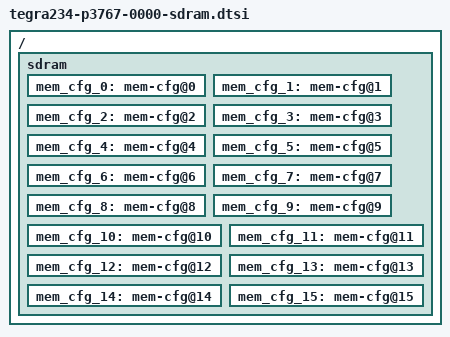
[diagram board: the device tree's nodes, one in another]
/*
 * SPDX-FileCopyrightText: Copyright (c) 2022 NVIDIA CORPORATION & AFFILIATES. All rights reserved.
 * SPDX-License-Identifier: LicenseRef-NvidiaProprietary
 *
 * NVIDIA CORPORATION, its affiliates and licensors retain all intellectual
 * property and proprietary rights in and to this material, related
 * documentation and any modifications thereto. Any use, reproduction,
 * disclosure or distribution of this material and related documentation
 * without an express license agreement from NVIDIA CORPORATION or
 * its affiliates is strictly prohibited.
 */

/ {
	sdram {
		mem_cfg_0: mem-cfg@0 {
		#include "tegra234-mb1-bct-p3767-0000-rc00-665mhz.dtsi"
		};

		mem_cfg_1: mem-cfg@1 {
		};

		mem_cfg_2: mem-cfg@2 {
		};

		mem_cfg_3: mem-cfg@3 {
		};

		mem_cfg_4: mem-cfg@4 {
		};

		mem_cfg_5: mem-cfg@5 {
		};

		mem_cfg_6: mem-cfg@6 {
		};

		mem_cfg_7: mem-cfg@7 {
		};

		mem_cfg_8: mem-cfg@8 {
		};

		mem_cfg_9: mem-cfg@9 {
		};

		mem_cfg_10: mem-cfg@10 {
		};

		mem_cfg_11: mem-cfg@11 {
		};

		mem_cfg_12: mem-cfg@12 {
		};

		mem_cfg_13: mem-cfg@13 {
		};

		mem_cfg_14: mem-cfg@14 {
		};

		mem_cfg_15: mem-cfg@15 {
		};
	};
};

